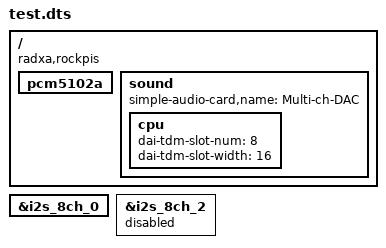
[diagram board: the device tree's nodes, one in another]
// Definitions for DummyDAC
/dts-v1/;
/plugin/;

/ {
        compatible = "radxa,rockpis", "rockchip,rk3308";

        fragment@0 {
                target = <&i2s_8ch_0>;

                __overlay__ {
                        #sound-dai-cells = <0>;
                        status = "okay";
                        };
               };
               
        fragment@1 {
                target = <&i2s_8ch_2>;

                __overlay__ {
                        #sound-dai-cells = <0>;
                        status = "disabled";
                        };
               };

        fragment@2 {
                target-path = "/";

                __overlay__ {
                        pcm5102a {
                                #sound-dai-cells = <0>;
                                status = "okay";
                                };
                        sound {
                                simple-audio-card,name = "Multi-ch-DAC";
                                status = "okay";
                                
                                cpu {
                                dai-tdm-slot-num = <8>;
                                dai-tdm-slot-width = <16>;
                                };
                            };
                    };
           };
 };
